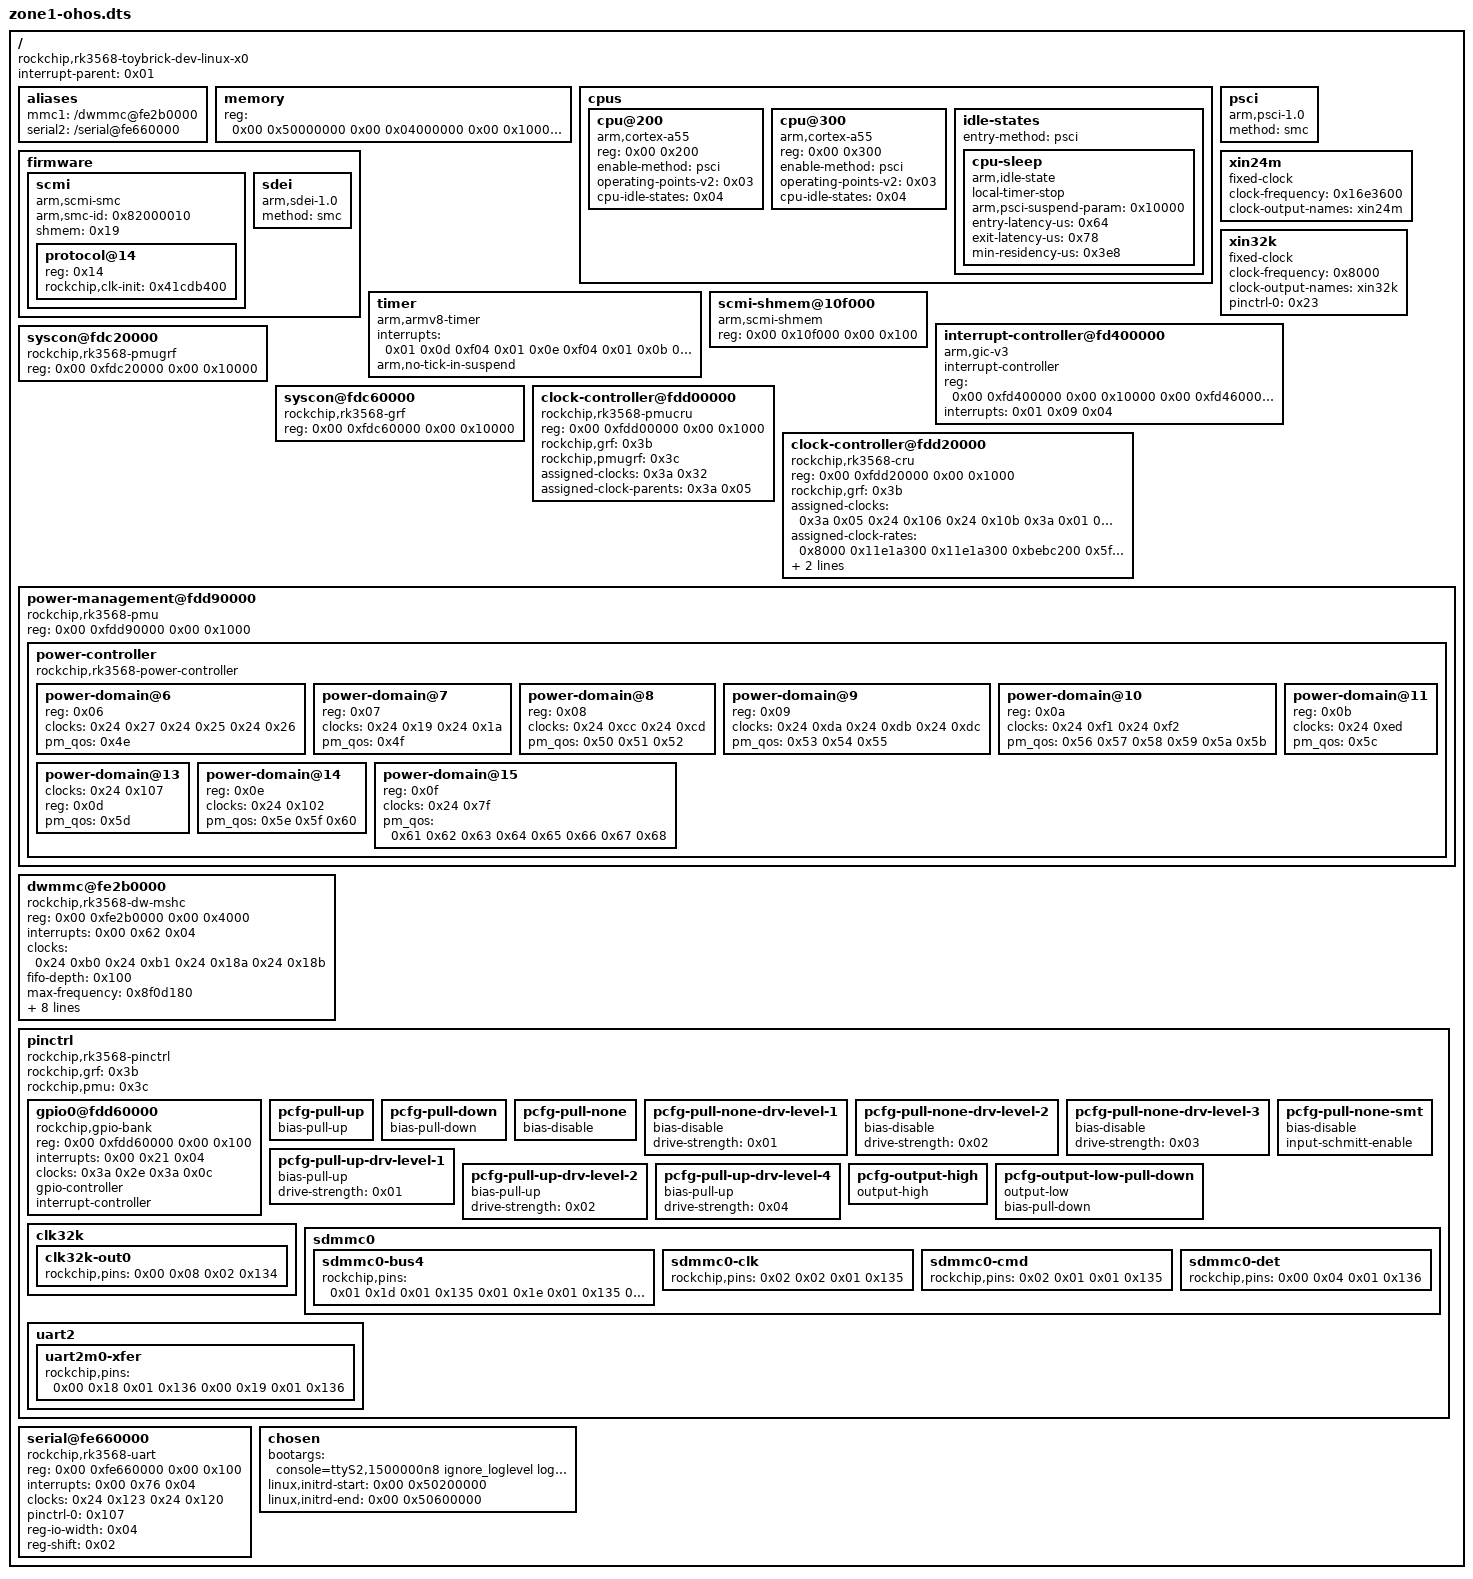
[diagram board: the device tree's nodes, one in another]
/dts-v1/;

/ {
	interrupt-parent = <0x01>;
	#address-cells = <0x02>;
	#size-cells = <0x02>;
	compatible = "rockchip,rk3568-toybrick-dev-linux-x0\0rockchip,rk3568";

	aliases {
		mmc1 = "/dwmmc@fe2b0000";
		serial2 = "/serial@fe660000";
	};

	memory {
		device_type = "memory";
		reg = <0x00 0x50000000 0x00 0x04000000 
		       0x00 0x10000000 0x00 0x20000000 
			   0x00 0x00 0x00 0x00 
			   0x00 0x00 0x00 0x00 
			   0x00 0x00 0x00 0x00 
			   0x00 0x00 0x00 0x00 
			   0x00 0x00 0x00 0x00 
			   0x00 0x00 0x00 0x00 
			   0x00 0x00 0x00 0x00 
			   0x00 0x00 0x00 0x00 
			   0x00 0x00 0x00 0x00 
			   0x00 0x00 0x00 0x00>;
	};

	cpus {
		#address-cells = <0x02>;
		#size-cells = <0x00>;

		// cpu@0 {
		// 	device_type = "cpu";
		// 	compatible = "arm,cortex-a55";
		// 	reg = <0x00 0x00>;
		// 	clocks = <0x02 0x00>;
		// 	#cooling-cells = <0x02>;
		// 	enable-method = "psci";
		// 	operating-points-v2 = <0x03>;
		// 	cpu-idle-states = <0x04>;
		// 	dynamic-power-coefficient = <0xbb>;
		// 	cpu-supply = <0x05>;
		// 	phandle = <0x1f>;
		// };

		// cpu@100 {
		// 	device_type = "cpu";
		// 	compatible = "arm,cortex-a55";
		// 	reg = <0x00 0x100>;
		// 	#cooling-cells = <0x02>;
		// 	enable-method = "psci";
		// 	operating-points-v2 = <0x03>;
		// 	cpu-idle-states = <0x04>;
		// 	phandle = <0x20>;
		// };

		cpu@200 {
			device_type = "cpu";
			compatible = "arm,cortex-a55";
			reg = <0x00 0x200>;
			#cooling-cells = <0x02>;
			enable-method = "psci";
			operating-points-v2 = <0x03>;
			cpu-idle-states = <0x04>;
			phandle = <0x21>;
		};

		cpu@300 {
			device_type = "cpu";
			compatible = "arm,cortex-a55";
			reg = <0x00 0x300>;
			#cooling-cells = <0x02>;
			enable-method = "psci";
			operating-points-v2 = <0x03>;
			cpu-idle-states = <0x04>;
			phandle = <0x22>;
		};

		idle-states {
			entry-method = "psci";

			cpu-sleep {
				compatible = "arm,idle-state";
				local-timer-stop;
				arm,psci-suspend-param = <0x10000>;
				entry-latency-us = <0x64>;
				exit-latency-us = <0x78>;
				min-residency-us = <0x3e8>;
				phandle = <0x04>;
			};
		};
	};

	firmware {

		scmi {
			compatible = "arm,scmi-smc";
			arm,smc-id = <0x82000010>;
			shmem = <0x19>;
			#address-cells = <0x01>;
			#size-cells = <0x00>;

			protocol@14 {
				reg = <0x14>;
				#clock-cells = <0x01>;
				rockchip,clk-init = <0x41cdb400>;
				phandle = <0x02>;
			};
		};

		sdei {
			compatible = "arm,sdei-1.0";
			method = "smc";
		};
	};

	psci {
		compatible = "arm,psci-1.0";
		method = "smc";
	};

	timer {
		compatible = "arm,armv8-timer";
		interrupts = <0x01 0x0d 0xf04 0x01 0x0e 0xf04 0x01 0x0b 0xf04 0x01 0x0a 0xf04>;
		arm,no-tick-in-suspend;
	};

	// important
	xin24m {
		compatible = "fixed-clock";
		clock-frequency = <0x16e3600>;
		clock-output-names = "xin24m";
		#clock-cells = <0x00>;
	};

	// important
	xin32k {
		compatible = "fixed-clock";
		clock-frequency = <0x8000>;
		clock-output-names = "xin32k";
		pinctrl-0 = <0x23>;
		pinctrl-names = "default";
		#clock-cells = <0x00>;
	};

	// important
	scmi-shmem@10f000 {
		compatible = "arm,scmi-shmem";
		reg = <0x00 0x10f000 0x00 0x100>;
		phandle = <0x19>;
	};

	interrupt-controller@fd400000 {
		compatible = "arm,gic-v3";
		#interrupt-cells = <0x03>;
		#address-cells = <0x02>;
		#size-cells = <0x02>;
		ranges;
		interrupt-controller;
		reg = <0x00 0xfd400000 0x00 0x10000 0x00 0xfd460000 0x00 0xc0000>;
		interrupts = <0x01 0x09 0x04>;
		phandle = <0x01>;
	};

	
	syscon@fdc20000 {
		compatible = "rockchip,rk3568-pmugrf\0syscon\0simple-mfd";
		reg = <0x00 0xfdc20000 0x00 0x10000>;
		phandle = <0x3c>;
	};

	syscon@fdc60000 {
		compatible = "rockchip,rk3568-grf\0syscon\0simple-mfd";
		reg = <0x00 0xfdc60000 0x00 0x10000>;
		phandle = <0x3b>;
	};

	
	clock-controller@fdd00000 {
		compatible = "rockchip,rk3568-pmucru";
		reg = <0x00 0xfdd00000 0x00 0x1000>;
		rockchip,grf = <0x3b>;
		rockchip,pmugrf = <0x3c>;
		#clock-cells = <0x01>;
		#reset-cells = <0x01>;
		assigned-clocks = <0x3a 0x32>;
		assigned-clock-parents = <0x3a 0x05>;
		phandle = <0x3a>;
	};

	clock-controller@fdd20000 {
		compatible = "rockchip,rk3568-cru";
		reg = <0x00 0xfdd20000 0x00 0x1000>;
		rockchip,grf = <0x3b>;
		#clock-cells = <0x01>;
		#reset-cells = <0x01>;
		assigned-clocks = <0x3a 0x05 0x24 0x106 0x24 0x10b 0x3a 0x01 0x3a 0x2b 0x24 0x03 0x24 0x19b 0x24 0x09 0x24 0x19c 0x24 0x19d 0x24 0x1a1 0x24 0x19e 0x24 0x19f 0x24 0x1a0 0x24 0x04 0x24 0x10d 0x24 0x10e 0x24 0x173 0x24 0x174 0x24 0x175 0x24 0x176 0x24 0xc9 0x24 0xca 0x24 0x06 0x24 0x7e 0x24 0x7f 0x24 0x3d 0x24 0x41 0x24 0x45 0x24 0x49 0x24 0x4d 0x24 0x4d 0x24 0x55 0x24 0x51 0x24 0x5d 0x24 0xdd>;
		assigned-clock-rates = <0x8000 0x11e1a300 0x11e1a300 0xbebc200 0x5f5e100 0x3b9aca00 0x1dcd6500 0x13d92d40 0xee6b280 0x7735940 0x5f5e100 0x3b9aca0 0x2faf080 0x17d7840 0x46cf7100 0x8f0d180 0x5f5e100 0x1dcd6500 0x17d78400 0x8f0d180 0x5f5e100 0x11e1a300 0x8f0d180 0x47868c00 0x17d78400 0x5f5e100 0x46cf7100 0x46cf7100 0x46cf7100 0x46cf7100 0x46cf7100 0x46cf7100 0x46cf7100 0x46cf7100 0x46cf7100 0x1dcd6500>;
		assigned-clock-parents = <0x3a 0x08 0x24 0x04 0x24 0x04>;
		phandle = <0x24>;
	};

	power-management@fdd90000 {
		compatible = "rockchip,rk3568-pmu\0syscon\0simple-mfd";
		reg = <0x00 0xfdd90000 0x00 0x1000>;

		power-controller {
			compatible = "rockchip,rk3568-power-controller";
			#power-domain-cells = <0x01>;
			#address-cells = <0x01>;
			#size-cells = <0x00>;
			phandle = <0x26>;

			power-domain@6 {
				reg = <0x06>;
				clocks = <0x24 0x27 0x24 0x25 0x24 0x26>;
				pm_qos = <0x4e>;
			};

			power-domain@7 {
				reg = <0x07>;
				clocks = <0x24 0x19 0x24 0x1a>;
				pm_qos = <0x4f>;
				#power-domain-cells = <0x00>;
			};

			power-domain@8 {
				reg = <0x08>;
				clocks = <0x24 0xcc 0x24 0xcd>;
				pm_qos = <0x50 0x51 0x52>;
				#power-domain-cells = <0x00>;
			};

			power-domain@9 {
				reg = <0x09>;
				clocks = <0x24 0xda 0x24 0xdb 0x24 0xdc>;
				pm_qos = <0x53 0x54 0x55>;
				#power-domain-cells = <0x00>;
			};

			power-domain@10 {
				reg = <0x0a>;
				clocks = <0x24 0xf1 0x24 0xf2>;
				pm_qos = <0x56 0x57 0x58 0x59 0x5a 0x5b>;
				#power-domain-cells = <0x00>;
			};

			power-domain@11 {
				reg = <0x0b>;
				clocks = <0x24 0xed>;
				pm_qos = <0x5c>;
				#power-domain-cells = <0x00>;
			};

			power-domain@13 {
				clocks = <0x24 0x107>;
				reg = <0x0d>;
				pm_qos = <0x5d>;
				#power-domain-cells = <0x00>;
			};

			power-domain@14 {
				reg = <0x0e>;
				clocks = <0x24 0x102>;
				pm_qos = <0x5e 0x5f 0x60>;
				#power-domain-cells = <0x00>;
			};

			power-domain@15 {
				reg = <0x0f>;
				clocks = <0x24 0x7f>;
				pm_qos = <0x61 0x62 0x63 0x64 0x65 0x66 0x67 0x68>;
				#power-domain-cells = <0x00>;
			};
		};
	};

	dwmmc@fe2b0000 {
		compatible = "rockchip,rk3568-dw-mshc\0rockchip,rk3288-dw-mshc";
		reg = <0x00 0xfe2b0000 0x00 0x4000>;
		interrupts = <0x00 0x62 0x04>;
		clocks = <0x24 0xb0 0x24 0xb1 0x24 0x18a 0x24 0x18b>;
		clock-names = "biu\0ciu\0ciu-drive\0ciu-sample";
		fifo-depth = <0x100>;
		max-frequency = <0x8f0d180>;
		resets = <0x24 0xd4>;
		reset-names = "reset";
		status = "okay";
		supports-sd;
		bus-width = <0x04>;
		cap-mmc-highspeed;
		cap-sd-highspeed;
		disable-wp;
		no-1-8-v;
		pinctrl-names = "default";
		pinctrl-0 = <0xc5 0xc6 0xc7 0xc8>;
	};

	pinctrl {
		compatible = "rockchip,rk3568-pinctrl";
		rockchip,grf = <0x3b>;
		rockchip,pmu = <0x3c>;
		#address-cells = <0x02>;
		#size-cells = <0x02>;
		ranges;

		gpio0@fdd60000 {
			compatible = "rockchip,gpio-bank";
			reg = <0x00 0xfdd60000 0x00 0x100>;
			interrupts = <0x00 0x21 0x04>;
			clocks = <0x3a 0x2e 0x3a 0x0c>;
			gpio-controller;
			#gpio-cells = <0x02>;
			interrupt-controller;
			#interrupt-cells = <0x02>;
			phandle = <0x3f>;
		};

		pcfg-pull-up {
			bias-pull-up;
			phandle = <0x136>;
		};

		pcfg-pull-down {
			bias-pull-down;
			phandle = <0x13e>;
		};

		pcfg-pull-none {
			bias-disable;
			phandle = <0x134>;
		};

		pcfg-pull-none-drv-level-1 {
			bias-disable;
			drive-strength = <0x01>;
			phandle = <0x138>;
		};

		pcfg-pull-none-drv-level-2 {
			bias-disable;
			drive-strength = <0x02>;
			phandle = <0x137>;
		};

		pcfg-pull-none-drv-level-3 {
			bias-disable;
			drive-strength = <0x03>;
			phandle = <0x13d>;
		};

		pcfg-pull-up-drv-level-1 {
			bias-pull-up;
			drive-strength = <0x01>;
			phandle = <0x13c>;
		};

		pcfg-pull-up-drv-level-2 {
			bias-pull-up;
			drive-strength = <0x02>;
			phandle = <0x135>;
		};

		pcfg-pull-up-drv-level-4 {
			bias-pull-up;
			drive-strength = <0x04>;
			phandle = <0x13a>;
		};

		pcfg-pull-none-smt {
			bias-disable;
			input-schmitt-enable;
			phandle = <0x139>;
		};

		pcfg-output-high {
			output-high;
			phandle = <0x13f>;
		};

		pcfg-output-low-pull-down {
			output-low;
			bias-pull-down;
			phandle = <0x13b>;
		};

		clk32k {

			clk32k-out0 {
				rockchip,pins = <0x00 0x08 0x02 0x134>;
				phandle = <0x23>;
			};
		};

		sdmmc0 {

			sdmmc0-bus4 {
				rockchip,pins = <0x01 0x1d 0x01 0x135 0x01 0x1e 0x01 0x135 0x01 0x1f 0x01 0x135 0x02 0x00 0x01 0x135>;
				phandle = <0xc5>;
			};

			sdmmc0-clk {
				rockchip,pins = <0x02 0x02 0x01 0x135>;
				phandle = <0xc6>;
			};

			sdmmc0-cmd {
				rockchip,pins = <0x02 0x01 0x01 0x135>;
				phandle = <0xc7>;
			};

			sdmmc0-det {
				rockchip,pins = <0x00 0x04 0x01 0x136>;
				phandle = <0xc8>;
			};
		};

		uart2 {

			uart2m0-xfer {
				rockchip,pins = <0x00 0x18 0x01 0x136 0x00 0x19 0x01 0x136>;
				phandle = <0x107>;
			};
		};

	};

	serial@fe660000 {
		compatible = "rockchip,rk3568-uart\0snps,dw-apb-uart";
		reg = <0x00 0xfe660000 0x00 0x100>;
		interrupts = <0x00 0x76 0x04>;
		clocks = <0x24 0x123 0x24 0x120>;
		clock-names = "baudclk\0apb_pclk";
		pinctrl-0 = <0x107>;
		pinctrl-names = "default";
		reg-io-width = <0x04>;
		reg-shift = <0x02>;
		status = "okay";
	};

	chosen {
		bootargs = "console=ttyS2,1500000n8 ignore_loglevel loglevel=8 initcall_debug clk_ignore_unused pd_ignore_unused bootslots=0 ohos.boot.eng_mode=on root=PARTUUID=614e0000-0000 hardware=rk3568 default_boot_device=fe2b0000.dwmmc rw rootwait ohos.required_mount.system=/dev/block/platform/fe2b0000.dwmmc/by-name/system@/usr@ext4@ro,barrier=1@wait,required ohos.required_mount.vendor=/dev/block/platform/fe2b0000.dwmmc/by-name/vendor@/vendor@ext4@ro,barrier=1@wait,required ohos.required_mount.misc=/dev/block/platform/fe2b0000.dwmmc/by-name/misc@none@none@none@wait,required ohos.required_mount.bootctrl=/dev/block/platform/fe2b0000.dwmmc/by-name/bootctrl@none@none@none@wait,required";
		linux,initrd-start = <0x00 0x50200000>;
		linux,initrd-end = <0x00 0x50600000>;
	};
};


// 请勿删除这段注释。裸启动修改集中放这里。需要启用时取消整段注释；需要关闭时注释整段。（已经通过反编译确定改动有效了）
// &{/} {
// 	memory {
// 		device_type = "memory";
// 		reg = <0x00 0x200000 0x00 0x8200000
// 		       0x00 0x9400000 0x00 0x76c00000
// 		       0x00 0x00 0x00 0x00
// 		       0x00 0x00 0x00 0x00
// 		       0x00 0x00 0x00 0x00
// 		       0x00 0x00 0x00 0x00
// 		       0x00 0x00 0x00 0x00
// 		       0x00 0x00 0x00 0x00
// 		       0x00 0x00 0x00 0x00
// 		       0x00 0x00 0x00 0x00
// 		       0x00 0x00 0x00 0x00
// 		       0x00 0x00 0x00 0x00>;
// 	};

// 	reserved-memory {
// 		#size-cells = <0x02>;
// 		ranges;
// 		#address-cells = <0x02>;

// 		hvisor@40400000 {
// 			no-map;
// 			reg = <0x00 0x40400000 0x00 0x4900000>;
// 		};

// 		ohos-zone1-bootarea {
// 			no-map;
// 			reg = <0x00 0x50000000 0x00 0x04000000>;
// 			// [0x5000_0000, 0x5020_0000), 2 MiB, device-tree-blob
// 			// [0x5020_0000, 0x5060_0000), 4 MiB, ramdisk
// 			// [0x5060_0000, 0x5360_0000), 48 MiB, kernel
// 			// [0x5360_0000, 0x5400_0000) free
// 		};

// 		ohos-zone1-memory {
// 			no-map;
// 			reg = <0x00 0x10000000 0x00 0x20000000>;
// 		};
// 	};

// 	chosen {
// 		bootargs = "console=ttyS2,1500000n8 ignore_loglevel loglevel=8 initcall_debug clk_ignore_unused pd_ignore_unused bootslots=0 ohos.boot.eng_mode=on root=PARTUUID=614e0000-0000 hardware=rk3568 default_boot_device=fe2b0000.dwmmc rw rootwait ohos.required_mount.system=/dev/block/platform/fe2b0000.dwmmc/by-name/system@/usr@ext4@ro,barrier=1@wait,required ohos.required_mount.vendor=/dev/block/platform/fe2b0000.dwmmc/by-name/vendor@/vendor@ext4@ro,barrier=1@wait,required ohos.required_mount.misc=/dev/block/platform/fe2b0000.dwmmc/by-name/misc@none@none@none@wait,required ohos.required_mount.bootctrl=/dev/block/platform/fe2b0000.dwmmc/by-name/bootctrl@none@none@none@wait,required";
// 		linux,initrd-start = <0x00 0xa200000>;
// 		linux,initrd-end = <0x00 0xa600000>;
// 	};
// };
